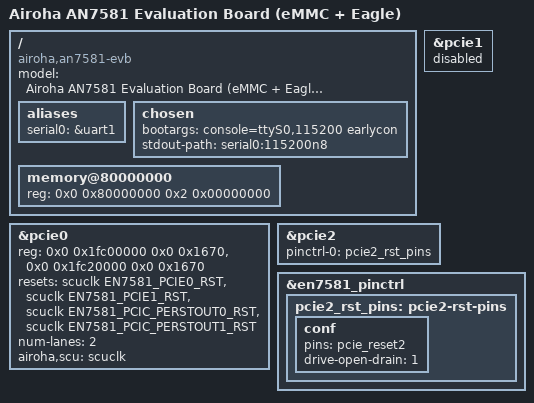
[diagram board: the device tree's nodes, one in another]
// SPDX-License-Identifier: (GPL-2.0-only OR BSD-2-Clause)
/dts-v1/;

#include "an7581-evb-emmc.dtsi"
#include "an7581-npu-mt7996.dtsi"

/ {
	model = "Airoha AN7581 Evaluation Board (eMMC + Eagle)";
	compatible = "airoha,an7581-evb", "airoha,an7581", "airoha,en7581";

	aliases {
		serial0 = &uart1;
	};

	chosen {
		bootargs = "console=ttyS0,115200 earlycon";
		stdout-path = "serial0:115200n8";
	};

	memory@80000000 {
		device_type = "memory";
		reg = <0x0 0x80000000 0x2 0x00000000>;
	};
};

&pcie0 {
	reg = <0x0 0x1fc00000 0x0 0x1670>,
	      <0x0 0x1fc20000 0x0 0x1670>;
	reg-names = "pcie-mac", "sec-pcie-mac";

	resets = <&scuclk EN7581_PCIE0_RST>,
		 <&scuclk EN7581_PCIE1_RST>,
		 <&scuclk EN7581_PCIC_PERSTOUT0_RST>,
		 <&scuclk EN7581_PCIC_PERSTOUT1_RST>;
	reset-names = "phy-lane0", "phy-lane1",
		      "perstout", "sec-perstout";

	num-lanes = <2>;

	airoha,scu = <&scuclk>;
};

&pcie1 {
	status = "disabled";
};

&pcie2 {
	pinctrl-names = "default";
	pinctrl-0 = <&pcie2_rst_pins>;
	status = "okay";
};

&en7581_pinctrl {
	pcie2_rst_pins: pcie2-rst-pins {
		conf {
			pins = "pcie_reset2";
			drive-open-drain = <1>;
		};
	};
};
